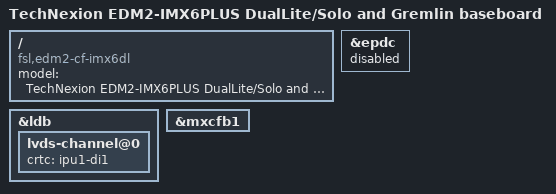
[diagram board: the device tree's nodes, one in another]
/*
 * Copyright 2017 Technexion Ltd.
 *
 * Author: Tapani Utriainen <tapani@technexion.com>
 *
 * This program is free software; you can redistribute it and/or modify
 * it under the terms of the GNU General Public License version 2 as
 * published by the Free Software Foundation.
 *
 */
/dts-v1/;
#define EDM1_FAIRY_ENABLE_SPDIF
#include <dt-bindings/interrupt-controller/irq.h>
#include "imx6dl.dtsi"
#include "imx6qdl-edm2-cf-pmic.dtsi"
#include "baseboard_edm2_gremlin.dtsi"

/ {
	model = "TechNexion EDM2-IMX6PLUS DualLite/Solo and Gremlin baseboard";
	compatible = "fsl,edm2-cf-imx6dl", "fsl,imx6dl";
};

&ldb {
	lvds-channel@0 {
		crtc = "ipu1-di0";
	};
	lvds-channel@0 {
		crtc = "ipu1-di1";
	};
};

&mxcfb1 {
	status = "okay";
};

&epdc {
	status = "disabled";
};
